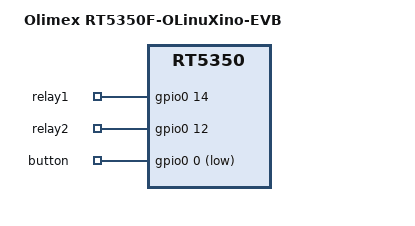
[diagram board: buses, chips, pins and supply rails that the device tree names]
/dts-v1/;

#include "rt5350_olimex_rt5350f-olinuxino.dtsi"

#include <dt-bindings/gpio/gpio.h>

/ {
	compatible = "olimex,rt5350f-olinuxino-evb", "ralink,rt5350-soc";
	model = "Olimex RT5350F-OLinuXino-EVB";

	gpio_export {
		compatible = "gpio-export";
		#size-cells = <0>;

		relay1 {
			gpio-export,name = "relay1";
			gpio-export,output = <0>;
			gpios = <&gpio0 14 GPIO_ACTIVE_HIGH>;
		};

		relay2 {
			gpio-export,name = "relay2";
			gpio-export,output = <0>;
			gpios = <&gpio0 12 GPIO_ACTIVE_HIGH>;
		};

		button {
			gpio-export,name = "button";
			gpios = <&gpio0 0 GPIO_ACTIVE_LOW>;
		};
	};
};
